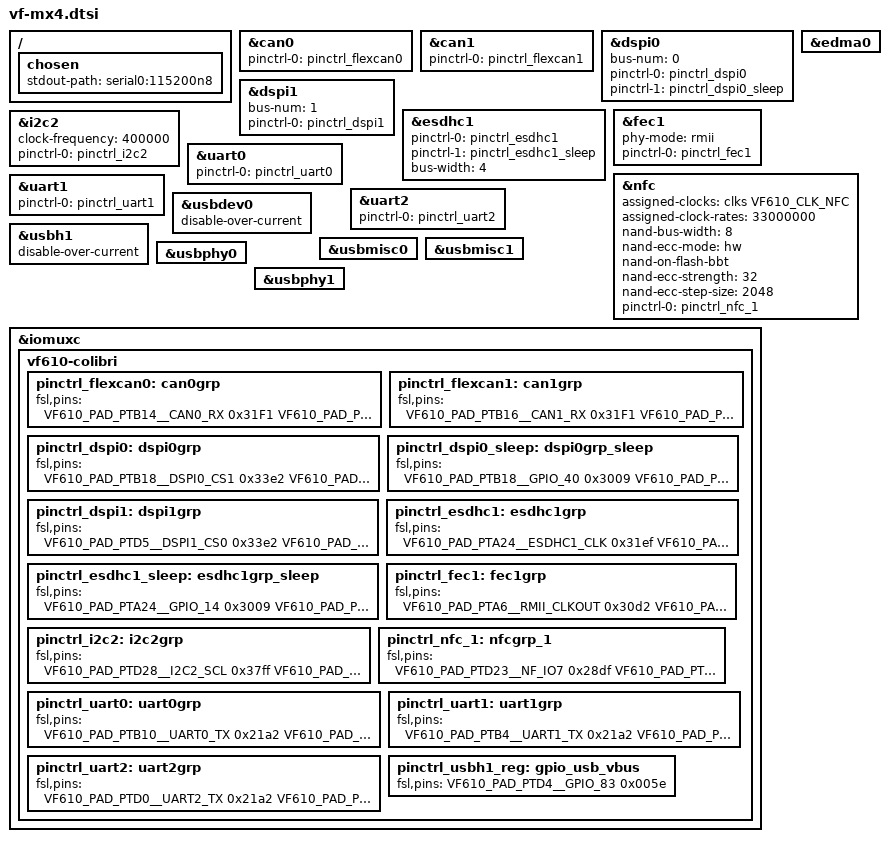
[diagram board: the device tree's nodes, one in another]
/*
 * Copyright 2015 Host Mobility AB
 *
 * This program is free software; you can redistribute it and/or modify
 * it under the terms of the GNU General Public License as published by
 * the Free Software Foundation; either version 2 of the License, or
 * (at your option) any later version.
 */

/ {
	chosen {
		stdout-path = "serial0:115200n8";
	};
};


&can0 {
	pinctrl-names = "default";
	pinctrl-0 = <&pinctrl_flexcan0>;
	status = "okay";
};

&can1 {
	pinctrl-names = "default";
	pinctrl-0 = <&pinctrl_flexcan1>;
	status = "okay";
};

&dspi0 {
	bus-num = <0>;
	pinctrl-names = "default", "sleep";
	pinctrl-0 = <&pinctrl_dspi0>;
	pinctrl-1 = <&pinctrl_dspi0_sleep>;
};


&dspi1 {
	bus-num = <1>;
	pinctrl-names = "default";
	pinctrl-0 = <&pinctrl_dspi1>;
};

&edma0 {
	status = "okay";
};

&esdhc1 {
	pinctrl-names = "default", "sleep";
	pinctrl-0 = <&pinctrl_esdhc1>;
	pinctrl-1 = <&pinctrl_esdhc1_sleep>;
	bus-width = <4>;
};

&fec1 {
	phy-mode = "rmii";
	pinctrl-names = "default";
	pinctrl-0 = <&pinctrl_fec1>;
};

&i2c2 {
	clock-frequency = <400000>;
	pinctrl-names = "default";
	pinctrl-0 = <&pinctrl_i2c2>;
};


&nfc {
	assigned-clocks = <&clks VF610_CLK_NFC>;
	assigned-clock-rates = <33000000>;
	nand-bus-width = <8>;
	nand-ecc-mode = "hw";
	nand-on-flash-bbt;
	nand-ecc-strength = <32>;
	nand-ecc-step-size = <2048>;
	pinctrl-names = "default";
	pinctrl-0 = <&pinctrl_nfc_1>;
	status = "okay";
};

&uart0 {
	pinctrl-names = "default";
	pinctrl-0 = <&pinctrl_uart0>;
};

&uart1 {
	pinctrl-names = "default";
	pinctrl-0 = <&pinctrl_uart1>;
};

&uart2 {
	pinctrl-names = "default";
	pinctrl-0 = <&pinctrl_uart2>;
};

&usbdev0 {
	disable-over-current;
	status = "okay";
};

&usbh1 {
	disable-over-current;
	status = "okay";
};

&usbmisc0 {
	status = "okay";
};

&usbmisc1 {
	status = "okay";
};

&usbphy0 {
	status = "okay";
};

&usbphy1 {
	status = "okay";
};

&iomuxc {
	vf610-colibri {
		pinctrl_flexcan0: can0grp {
			fsl,pins = <
				VF610_PAD_PTB14__CAN0_RX	0x31F1
				VF610_PAD_PTB15__CAN0_TX	0x31F2
			>;
		};

		pinctrl_flexcan1: can1grp {
			fsl,pins = <
				VF610_PAD_PTB16__CAN1_RX	0x31F1
				VF610_PAD_PTB17__CAN1_TX	0x31F2
			>;
		};

		pinctrl_dspi0: dspi0grp {
			fsl,pins = <
				VF610_PAD_PTB18__DSPI0_CS1		0x33e2
				VF610_PAD_PTB20__DSPI0_SIN		0x33e1
				VF610_PAD_PTB21__DSPI0_SOUT		0x33e2
				VF610_PAD_PTB22__DSPI0_SCK		0x33e2
			>;
		};

		pinctrl_dspi0_sleep: dspi0grp_sleep {
			fsl,pins = <
				VF610_PAD_PTB18__GPIO_40		0x3009
				VF610_PAD_PTB20__GPIO_42		0x3009
				VF610_PAD_PTB21__GPIO_43		0x3009
				VF610_PAD_PTB22__GPIO_44		0x3009
			>;
		};


		pinctrl_dspi1: dspi1grp {
			fsl,pins = <
				VF610_PAD_PTD5__DSPI1_CS0		0x33e2
				VF610_PAD_PTD6__DSPI1_SIN		0x33e1
				VF610_PAD_PTD7__DSPI1_SOUT		0x33e2
				VF610_PAD_PTD8__DSPI1_SCK		0x33e2
			>;
		};

		pinctrl_esdhc1: esdhc1grp {
			fsl,pins = <
				VF610_PAD_PTA24__ESDHC1_CLK	0x31ef
				VF610_PAD_PTA25__ESDHC1_CMD	0x31ef
				VF610_PAD_PTA26__ESDHC1_DAT0	0x31ef
				VF610_PAD_PTA27__ESDHC1_DAT1	0x31ef
				VF610_PAD_PTA28__ESDHC1_DATA2	0x31ef
				VF610_PAD_PTA29__ESDHC1_DAT3	0x31ef
			>;
		};

		pinctrl_esdhc1_sleep: esdhc1grp_sleep {
			fsl,pins = <
				VF610_PAD_PTA24__GPIO_14	0x3009
				VF610_PAD_PTA25__GPIO_15	0x3009
				VF610_PAD_PTA26__GPIO_16	0x3009
				VF610_PAD_PTA27__GPIO_17	0x3009
				VF610_PAD_PTA28__GPIO_18	0x3009
				VF610_PAD_PTA29__GPIO_19	0x3009
			>;
		};

		pinctrl_fec1: fec1grp {
			fsl,pins = <
				VF610_PAD_PTA6__RMII_CLKOUT		0x30d2
				VF610_PAD_PTC9__ENET_RMII1_MDC		0x30d2
				VF610_PAD_PTC10__ENET_RMII1_MDIO	0x30d3
				VF610_PAD_PTC11__ENET_RMII1_CRS		0x30d1
				VF610_PAD_PTC12__ENET_RMII1_RXD1		0x30d1
				VF610_PAD_PTC13__ENET_RMII1_RXD0	0x30d1
				VF610_PAD_PTC14__ENET_RMII1_RXER	0x30d1
				VF610_PAD_PTC15__ENET_RMII1_TXD1	0x30d2
				VF610_PAD_PTC16__ENET_RMII1_TXD0	0x30d2
				VF610_PAD_PTC17__ENET_RMII1_TXEN	0x30d2
			>;
		};

		pinctrl_i2c2: i2c2grp {
			fsl,pins = <
				VF610_PAD_PTD28__I2C2_SCL		0x37ff
				VF610_PAD_PTD27__I2C2_SDA		0x37ff
			>;
		};


		pinctrl_nfc_1: nfcgrp_1 {
			fsl,pins = <
				VF610_PAD_PTD23__NF_IO7		0x28df
				VF610_PAD_PTD22__NF_IO6		0x28df
				VF610_PAD_PTD21__NF_IO5		0x28df
				VF610_PAD_PTD20__NF_IO4		0x28df
				VF610_PAD_PTD19__NF_IO3		0x28df
				VF610_PAD_PTD18__NF_IO2		0x28df
				VF610_PAD_PTD17__NF_IO1		0x28df
				VF610_PAD_PTD16__NF_IO0		0x28df
				VF610_PAD_PTB24__NF_WE_B	0x28c2
				VF610_PAD_PTB25__NF_CE0_B	0x28c2
				VF610_PAD_PTB27__NF_RE_B	0x28c2
				VF610_PAD_PTC26__NF_RB_B	0x283d
				VF610_PAD_PTC27__NF_ALE		0x28c2
				VF610_PAD_PTC28__NF_CLE		0x28c2
			>;
		};

		pinctrl_uart0: uart0grp {
			fsl,pins = <
				VF610_PAD_PTB10__UART0_TX		0x21a2
				VF610_PAD_PTB11__UART0_RX		0x21a1
			>;
		};

		pinctrl_uart1: uart1grp {
			fsl,pins = <
				VF610_PAD_PTB4__UART1_TX		0x21a2
				VF610_PAD_PTB5__UART1_RX		0x21a1
			>;
		};

		pinctrl_uart2: uart2grp {
			fsl,pins = <
				VF610_PAD_PTD0__UART2_TX		0x21a2
				VF610_PAD_PTD1__UART2_RX		0x21a1
				VF610_PAD_PTD2__UART2_RTS		0x21a2
				VF610_PAD_PTD3__UART2_CTS		0x21a1
			>;
		};

		pinctrl_usbh1_reg: gpio_usb_vbus {
			fsl,pins = <
				VF610_PAD_PTD4__GPIO_83			0x005e
			>;
		};
	};
};
